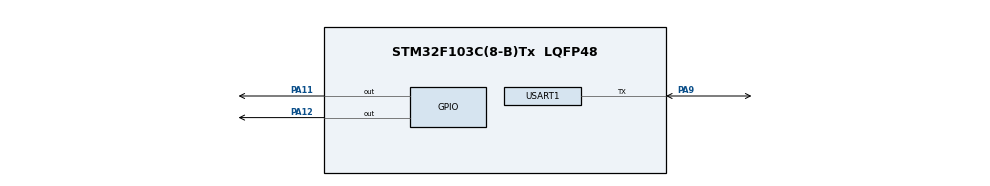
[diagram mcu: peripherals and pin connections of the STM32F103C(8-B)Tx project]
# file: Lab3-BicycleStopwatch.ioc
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Mcu.Family=STM32F1
Mcu.Name=STM32F103C(8-B)Tx
Mcu.Package=LQFP48
NVIC.PriorityGroup=NVIC_PRIORITYGROUP_4
PA10.Signal=USART1_RX
PA11.Signal=GPIO_Output
PA12.Signal=GPIO_Output
PA9.Mode=Half_duplex(single_wire_mode)
PA9.Signal=USART1_TX
ProjectManager.HeapSize=0x200
ProjectManager.StackSize=0x400
ProjectManager.TargetToolchain=MDK-ARM V5
RCC.APB1Freq_Value=8000000
RCC.APB2Freq_Value=8000000
board=Lab3-BicycleStopwatch

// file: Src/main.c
/**
  ******************************************************************************
  * File Name          : main.c
  * Description        : Main program body
  ******************************************************************************
  *
  * COPYRIGHT(c) 2016 STMicroelectronics
  *
  * Redistribution and use in source and binary forms, with or without modification,
  * are permitted provided that the following conditions are met:
  *   1. Redistributions of source code must retain the above copyright notice,
  *      this list of conditions and the following disclaimer.
  *   2. Redistributions in binary form must reproduce the above copyright notice,
  *      this list of conditions and the following disclaimer in the documentation
  *      and/or other materials provided with the distribution.
  *   3. Neither the name of STMicroelectronics nor the names of its contributors
  *      may be used to endorse or promote products derived from this software
  *      without specific prior written permission.
  *
  * THIS SOFTWARE IS PROVIDED BY THE COPYRIGHT HOLDERS AND CONTRIBUTORS "AS IS"
  * AND ANY EXPRESS OR IMPLIED WARRANTIES, INCLUDING, BUT NOT LIMITED TO, THE
  * IMPLIED WARRANTIES OF MERCHANTABILITY AND FITNESS FOR A PARTICULAR PURPOSE ARE
  * DISCLAIMED. IN NO EVENT SHALL THE COPYRIGHT HOLDER OR CONTRIBUTORS BE LIABLE
  * FOR ANY DIRECT, INDIRECT, INCIDENTAL, SPECIAL, EXEMPLARY, OR CONSEQUENTIAL
  * DAMAGES (INCLUDING, BUT NOT LIMITED TO, PROCUREMENT OF SUBSTITUTE GOODS OR
  * SERVICES; LOSS OF USE, DATA, OR PROFITS; OR BUSINESS INTERRUPTION) HOWEVER
  * CAUSED AND ON ANY THEORY OF LIABILITY, WHETHER IN CONTRACT, STRICT LIABILITY,
  * OR TORT (INCLUDING NEGLIGENCE OR OTHERWISE) ARISING IN ANY WAY OUT OF THE USE
  * OF THIS SOFTWARE, EVEN IF ADVISED OF THE POSSIBILITY OF SUCH DAMAGE.
  *
  ******************************************************************************
  */
#include "stm32f1xx_hal.h"

UART_HandleTypeDef huart1;
TIM_HandleTypeDef TIM_Handle;
int flag = 0,TIMflag = 0;
int loopCount = 0,lastLoopCount = 0,totalSecond = 0;
/* USER CODE BEGIN PV */
/* Private variables ---------------------------------------------------------*/

/* USER CODE END PV */

void SystemClock_Config(void);
static void MX_GPIO_Init(void);
static void MX_USART1_UART_Init(void);

/* USER CODE BEGIN PFP */
/* Private function prototypes -----------------------------------------------*/

/* USER CODE END PFP */

/* USER CODE BEGIN 0 */
void uart_init(UART_HandleTypeDef* UartHandle){
	UartHandle->Instance = USART1;
	UartHandle->Init.BaudRate = 9600;
	UartHandle->Init.WordLength = UART_WORDLENGTH_8B;
	UartHandle->Init.StopBits = UART_STOPBITS_1;
	UartHandle->Init.Parity = UART_PARITY_NONE;
	UartHandle->Init.HwFlowCtl = UART_HWCONTROL_NONE;
	UartHandle->Init.Mode = UART_MODE_TX_RX;

	HAL_UART_Init(UartHandle);
}
void NVIC_Init(){
    // enable IT
    HAL_NVIC_SetPriority(EXTI15_10_IRQn,0,0);
    HAL_NVIC_EnableIRQ(EXTI15_10_IRQn);
}
void HAL_GPIO_EXTI_Callback(uint16_t GPIO_Pin){
	if(GPIO_Pin!=GPIO_PIN_12){
		UNUSED(GPIO_Pin);
  }else{
		if(flag==0){
	    flag=1;
	    loopCount++;
		}
  }
}
void HAL_TIM_PeriodElapsedCallback(TIM_HandleTypeDef *htim){
  TIMflag = 1;
	totalSecond++;
}

void TIM_init(){
	TIM_Handle.Instance = TIM3;
	TIM_Handle.Init.Prescaler = 8000;
	TIM_Handle.Init.CounterMode = TIM_COUNTERMODE_UP;
	TIM_Handle.Init.Period = 199;	//200ms

	HAL_NVIC_SetPriority(TIM3_IRQn,0,0);
	HAL_NVIC_EnableIRQ(TIM3_IRQn);

	HAL_TIM_Base_Init(&TIM_Handle);
	HAL_TIM_Base_Start_IT(&TIM_Handle);
}
//int __io_putchar(uint8_t ch){
//	return HAL_UART_Transmit(&huart1,(uint8_t*)&ch, 1, 500);
//}
//int fputc(int ch, FILE *f) {
//	if(f==stdout){
//		return HAL_UART_Transmit(&huart1,(uint8_t*)&ch, 1, 500);
//	}else{
//		return 0;
//	}
//}
#ifdef __GNUC__
  /* With GCC/RAISONANCE, small printf (option LD Linker->Libraries->Small printf
     set to 'Yes') calls __io_putchar() */
  #define PUTCHAR_PROTOTYPE int __io_putchar(int ch)
#else
  #define PUTCHAR_PROTOTYPE int fputc(int ch, FILE *f)
#endif /* __GNUC__ */
/**
  * @brief  Retargets the C library printf function to the USART.
  * @param  None
  * @retval None
  */
PUTCHAR_PROTOTYPE
{
  /* Place your implementation of fputc here */
  /* e.g. write a character to the EVAL_COM1 and Loop until the end of transmission */
  HAL_UART_Transmit(&huart1, (uint8_t *)&ch, 1, 0xFFFF);

  return ch;
}
/* USER CODE END 0 */

int main(void)
{

  /* MCU Configuration----------------------------------------------------------*/

  /* Reset of all peripherals, Initializes the Flash interface and the Systick. */
  HAL_Init();

  /* Configure the system clock */
  SystemClock_Config();

  /* Initialize all configured peripherals */
  MX_GPIO_Init();
  MX_USART1_UART_Init();

  /* USER CODE BEGIN 2 */
	UART_HandleTypeDef UartHandle;
	uart_init(&UartHandle);
	NVIC_Init();
	TIM_init();
  /* USER CODE END 2 */

  /* Infinite loop */
  /* USER CODE BEGIN WHILE */
	GPIO_PinState state;
  while (1)
  {
  /* USER CODE END WHILE */

  /* USER CODE BEGIN 3 */
//		HAL_UART_Transmit(&UartHandle,(uint8_t*)"hello\r\n", 7, 500);
//		HAL_GPIO_TogglePin(GPIOA, GPIO_PIN_11);
//		HAL_Delay(500);

//		state = HAL_GPIO_ReadPin(GPIOA, GPIO_PIN_11);
//		if(state==GPIO_PIN_RESET){	//RESET means press
//			//HAL_UART_Transmit(&UartHandle,(uint8_t*)"pressed\r\n", 9, 500);
//			printf("pressed\r\n");
//		}else{
//			//HAL_UART_Transmit(&UartHandle,(uint8_t*)"released\r\n", 10, 500);
//			printf("released\r\n");
//		}
//		HAL_Delay(200);

//		if (flag == 1){
//        flag = 0;
//				printf("pressed\r\n");
//    }
//		printf("flag=%d,count=%d\r\n",flag,count);
//		HAL_Delay(500);

		if (flag == 1){
        flag = 0;
    }
		if (TIMflag == 1){
        TIMflag = 0;
				if(totalSecond%5==0){
					printf("speed = %f\t", (loopCount-lastLoopCount)*1.2*3.14);
					lastLoopCount = loopCount;
					printf("total distance: %f\r\n", loopCount*1.2*3.14);
				}
		}
		HAL_Delay(200);

  }
  /* USER CODE END 3 */

}

/** System Clock Configuration
*/
void SystemClock_Config(void)
{

  RCC_OscInitTypeDef RCC_OscInitStruct;
  RCC_ClkInitTypeDef RCC_ClkInitStruct;

  RCC_OscInitStruct.OscillatorType = RCC_OSCILLATORTYPE_HSI;
  RCC_OscInitStruct.HSIState = RCC_HSI_ON;
  RCC_OscInitStruct.HSICalibrationValue = 16;
  RCC_OscInitStruct.PLL.PLLState = RCC_PLL_NONE;
  HAL_RCC_OscConfig(&RCC_OscInitStruct);

  RCC_ClkInitStruct.ClockType = RCC_CLOCKTYPE_HCLK|RCC_CLOCKTYPE_SYSCLK
                              |RCC_CLOCKTYPE_PCLK1|RCC_CLOCKTYPE_PCLK2;
  RCC_ClkInitStruct.SYSCLKSource = RCC_SYSCLKSOURCE_HSI;
  RCC_ClkInitStruct.AHBCLKDivider = RCC_SYSCLK_DIV1;
  RCC_ClkInitStruct.APB1CLKDivider = RCC_HCLK_DIV1;
  RCC_ClkInitStruct.APB2CLKDivider = RCC_HCLK_DIV1;
  HAL_RCC_ClockConfig(&RCC_ClkInitStruct, FLASH_LATENCY_0);

  HAL_SYSTICK_Config(HAL_RCC_GetHCLKFreq()/1000);

  HAL_SYSTICK_CLKSourceConfig(SYSTICK_CLKSOURCE_HCLK);

  /* SysTick_IRQn interrupt configuration */
  HAL_NVIC_SetPriority(SysTick_IRQn, 0, 0);
}

/* USART1 init function */
void MX_USART1_UART_Init(void)
{

  huart1.Instance = USART1;
  huart1.Init.BaudRate = 115200;
  huart1.Init.WordLength = UART_WORDLENGTH_8B;
  huart1.Init.StopBits = UART_STOPBITS_1;
  huart1.Init.Parity = UART_PARITY_NONE;
  huart1.Init.Mode = UART_MODE_TX_RX;
  huart1.Init.HwFlowCtl = UART_HWCONTROL_NONE;
  huart1.Init.OverSampling = UART_OVERSAMPLING_16;
  HAL_HalfDuplex_Init(&huart1);

}

/** Configure pins as
        * Analog
        * Input
        * Output
        * EVENT_OUT
        * EXTI
*/
void MX_GPIO_Init(void)
{

  GPIO_InitTypeDef GPIO_InitStruct;

  /* GPIO Ports Clock Enable */
  __HAL_RCC_GPIOA_CLK_ENABLE();

  /*Configure GPIO pin Output Level */
  //HAL_GPIO_WritePin(GPIOA, GPIO_PIN_11|GPIO_PIN_12, GPIO_PIN_RESET);

  /*Configure GPIO pins : PA11 PA12 */
  GPIO_InitStruct.Pin = GPIO_PIN_11;
//  GPIO_InitStruct.Mode = GPIO_MODE_OUTPUT_PP;
//  GPIO_InitStruct.Speed = GPIO_SPEED_FREQ_LOW;
	GPIO_InitStruct.Mode = GPIO_MODE_INPUT;
	GPIO_InitStruct.Pull = GPIO_PULLUP;
  GPIO_InitStruct.Speed = GPIO_SPEED_FREQ_LOW;
	HAL_GPIO_Init(GPIOA, &GPIO_InitStruct);

  GPIO_InitStruct.Pin = GPIO_PIN_12;
	GPIO_InitStruct.Mode = GPIO_MODE_IT_FALLING;
	GPIO_InitStruct.Pull = GPIO_PULLUP;
  GPIO_InitStruct.Speed = GPIO_SPEED_FREQ_LOW;
	HAL_GPIO_Init(GPIOA, &GPIO_InitStruct);

}

/************************ (C) COPYRIGHT STMicroelectronics *****END OF FILE****/
